# DS_CM3 register map
Vendor: ARM Ltd.; Series: ARM Cortex M3; File version: 1.0
CPU: CM3 r2p1, little endian, MPU, no FPU, 3 interrupt priority bits
Registers are 32-bit, read-write, reset 0x0 unless marked. A register's access mark holds for its fields unless they carry their own. Offsets are from the block's base; [hi:lo] are bit positions; {n}, {i} and the like mark numbered series.

## SYSCTRL — System Control
Base 0x4001F000
0x00 REMAP — Remap Control Register
0x04 PMUCTRL — PMU Control Register
0x08 RESETOP — Reset Option Register
0x10 RSTINFO — Reset Information Register

## SPIEXT — Synchronous Serial Port (PL022) extern
Base 0x40020000
Same registers: SPICLCD 0x40021000, SPIADC 0x40025000, SPISH0 0x40026000, SPISH1 0x40027000
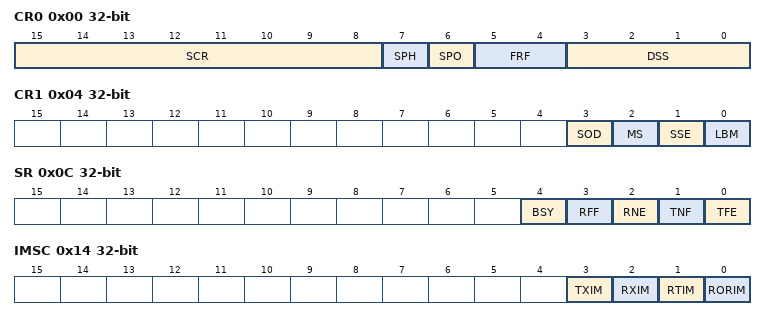
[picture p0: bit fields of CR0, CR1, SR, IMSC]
0x00 CR0 — Control register 0
  [15:8] SCR — Serial clock rate
  [7] SPH — SSPCLKOUT phase
  [6] SPO — SSPCLKOUT polarity
  [5:4] FRF — Frame format
  [3:0] DSS — Data Size Select
0x04 CR1 — Control register 1
  [3] SOD — Slave-mode output disable
  [2] MS — Master or slave mode select
  [1] SSE — Synchronous serial port enable
  [0] LBM — Loop back mode
0x08 DR — Data register
  [15:0] Data — Transmit/Receive FIFO
0x0C SR ro — Status register
  [4] BSY — PrimeCell SSP busy flag
  [3] RFF — Receive FIFO full
  [2] RNE — Receive FIFO not empty
  [1] TNF — Transmit FIFO not full
  [0] TFE — Transmit FIFO empty
0x10 CPSR — Clock prescale register
  [7:0] CPSDVSR — Clock prescale divisor
0x14 IMSC — Interrupt mask set or clear register
  [3] TXIM — Transmit FIFO interrupt mask
  [2] RXIM — Receive FIFO interrupt mask
  [1] RTIM — Receive timeout interrupt mask
  [0] RORIM — Receive overrun interrupt mask
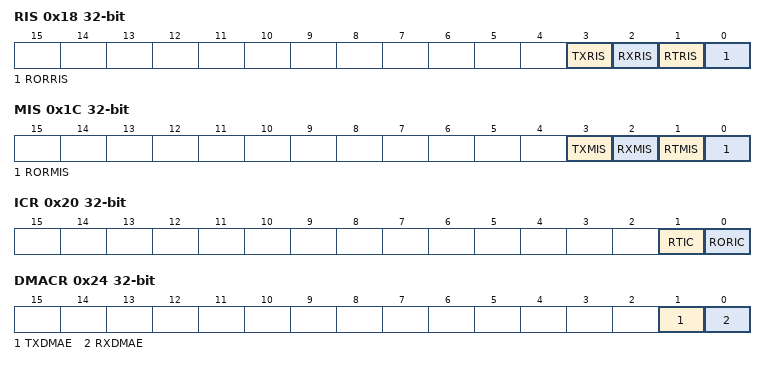
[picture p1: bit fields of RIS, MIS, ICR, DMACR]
0x18 RIS ro — Raw interrupt status register
  [3] TXRIS — transmit FIFOraw interrupt state
  [2] RXRIS — receive FIFO raw interrupt state
  [1] RTRIS — receive timeout raw interrupt state
  [0] RORRIS — receive over run raw interrupt state
0x1C MIS ro — Masked interrupt status register
  [3] TXMIS — transmit FIFO masked interrupt state
  [2] RXMIS — receive FIFO masked interrupt state
  [1] RTMIS — receive timeout masked interrupt state
  [0] RORMIS — receive over run masked interrupt state
0x20 ICR wo — Interrupt clear register
  [1] RTIC — Clears the SSPRTINTR interrupt
  [0] RORIC — Clears the SSPRORINTR interrupt
0x24 DMACR — DMA control register
  [1] TXDMAE — Transmit DMA Enable
  [0] RXDMAE — Receive DMA Enable

## I2CCLCD — Simple I2C peripheral
Base 0x40022000
Same registers: I2CAUDIO 0x40023000, I2CSH0 0x40029000, I2CSH1 0x4002A000
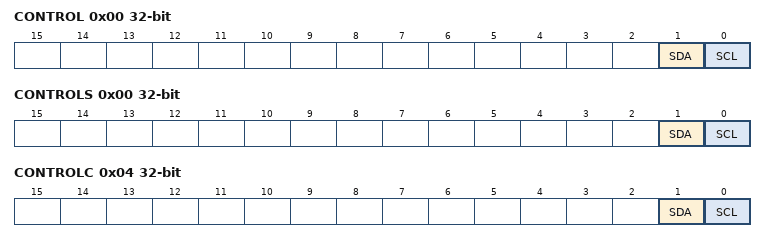
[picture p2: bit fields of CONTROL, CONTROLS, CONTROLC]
0x00 CONTROL ro — Control Status
  [1] SDA — Serial data line
  [0] SCL — Serial clock line
0x00 CONTROLS wo (alternate view of CONTROL) — Control Set
  [1] SDA — Serial data line
  [0] SCL — Serial clock line
0x04 CONTROLC wo — Control Clear
  [1] SDA — Serial data line
  [0] SCL — Serial clock line

## I2S — simple audio I2S peripheral
Base 0x40024000
0x00 CONTROL
0x04 STATUS ro
0x08 ERROR ro — Error Status Register
0x08 ERRORCLR wo (alternate view of ERROR) — Error Clear Register
0x0C DIVIDE — Divide ratio Register
0x10 TXBUF wo — Transmit Buffer
0x14 RXBUF ro — Receive Buffer
0x300 ITCR — Integration Test Control Register
0x304 ITIP1 wo — Integration Test Input Register 1
0x308 ITOP1 wo — Integration Test Output Register 1

## FPGASYS — FPGA System Control I/O
Base 0x40028000
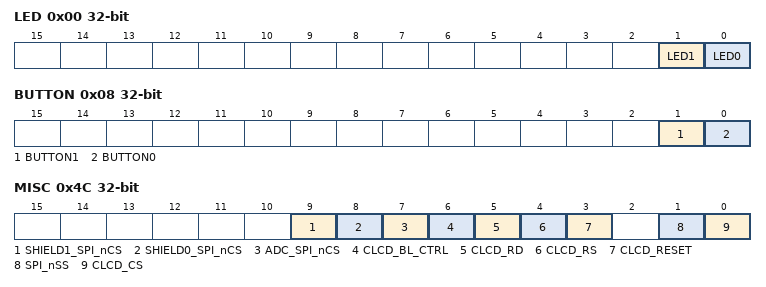
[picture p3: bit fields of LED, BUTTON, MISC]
0x00 LED — LED Connections
  [1] LED1
    0=Off (LED is off); 1=On (LED is on)
  [0] LED0
    0=Off (LED is off); 1=On (LED is on)
0x08 BUTTON — Button Connections
  [1] BUTTON1
    0=Off (BUTTON is off); 1=On (BUTTON is on)
  [0] BUTTON0
    0=Off (BUTTON is off); 1=On (BUTTON is on)
0x10 CLK1HZ ro — 1Hz Up Counter
0x14 CLK100HZ ro — 100Hz Up Counter
0x18 COUNTER — Cycle up counter
0x1C PRESCALER — Reload value for prescaler counter
0x20 PSCNTR — Prescale Counter
0x4C MISC — Misc. Control
  [9] SHIELD1_SPI_nCS, [8] SHIELD0_SPI_nCS, [7] ADC_SPI_nCS, [6] CLCD_BL_CTRL, [5] CLCD_RD, [4] CLCD_RS, [3] CLCD_RESET, [1] SPI_nSS, [0] CLCD_CS

## SCC — Serial Communication Controller
Base 0x4002F000
0x00 CFG_REG0 — Configuration register 0
  [0] REMAP — REMAP Block RAM to ZBT
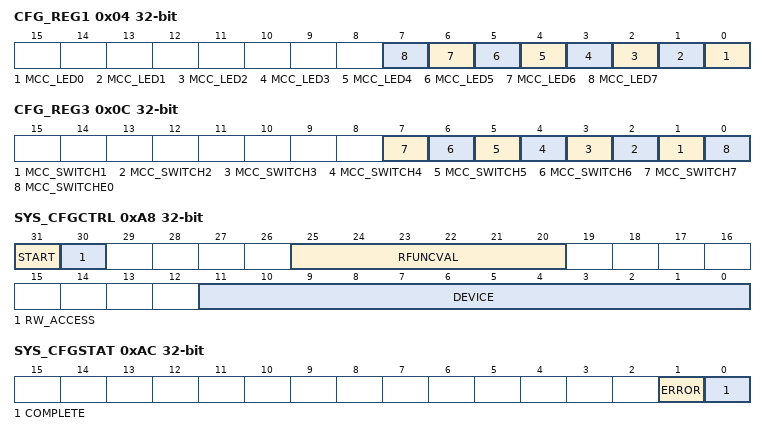
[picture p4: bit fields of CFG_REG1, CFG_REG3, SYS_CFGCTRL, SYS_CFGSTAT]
0x04 CFG_REG1 — Configuration register 1
  [all] fields
    0=Off (LED is off); 1=On (LED is on)
  [n] MCC_LED{n} (n=0..7)
0x08 CFG_REG2 ro — Configuration register 2
0x0C CFG_REG3 ro — Configuration register 3
  [all] fields
    0=Off (Switch is off); 1=On (Switch is on)
  [n] MCC_SWITCH{n} (n=1..7)
  [0] MCC_SWITCHE0 — MCC switch 0
0x10 CFG_REG4 ro — Configuration register 4
  [3:0] BRDREV — Board Revision
0xA0 SYS_CFGDATA_RTN — System configuration data register RTN
0xA4 SYS_CFGDATA_OUT — System configuration data register OUT
0xA8 SYS_CFGCTRL — System configuration control register
  [31] START — Start: generates interrupt on write to this bit
  [30] RW_ACCESS — Read/Write Access
  [25:20] RFUNCVAL — Function value
  [11:0] DEVICE — Device (value of 0/1/2 for supported clocks
0xAC SYS_CFGSTAT — System configuration status register
  [1] ERROR — Error Flag
  [0] COMPLETE — Complete Flag
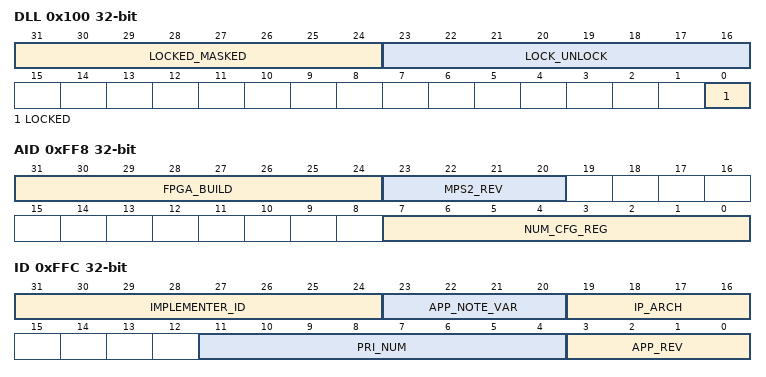
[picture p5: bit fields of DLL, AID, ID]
0x100 DLL — DLL Lock Register
  [31:24] LOCKED_MASKED — Error Flag
  [23:16] LOCK_UNLOCK — Complete Flag
  [0] LOCKED — Complete Flag
0xFF8 AID ro
  [31:24] FPGA_BUILD — FPGA Build Number
  [23:20] MPS2_REV — V2M-MPS2 target Board Revision
    0=A (Revision A); 1=B (Revision B); 2=C (Revision C)
  [7:0] NUM_CFG_REG — Number of SCC configuration register
0xFFC ID ro — AID register
  [31:24] IMPLEMENTER_ID — Implementer ID: 0x41 = ARM
    65=ARM
  [23:20] APP_NOTE_VAR — Application note IP variant number
  [19:16] IP_ARCH — IP Architecture
    4=AHB
  [11:4] PRI_NUM — Primary Part Number: 383 = AN383
  [3:0] APP_REV — Application note IP revision number
